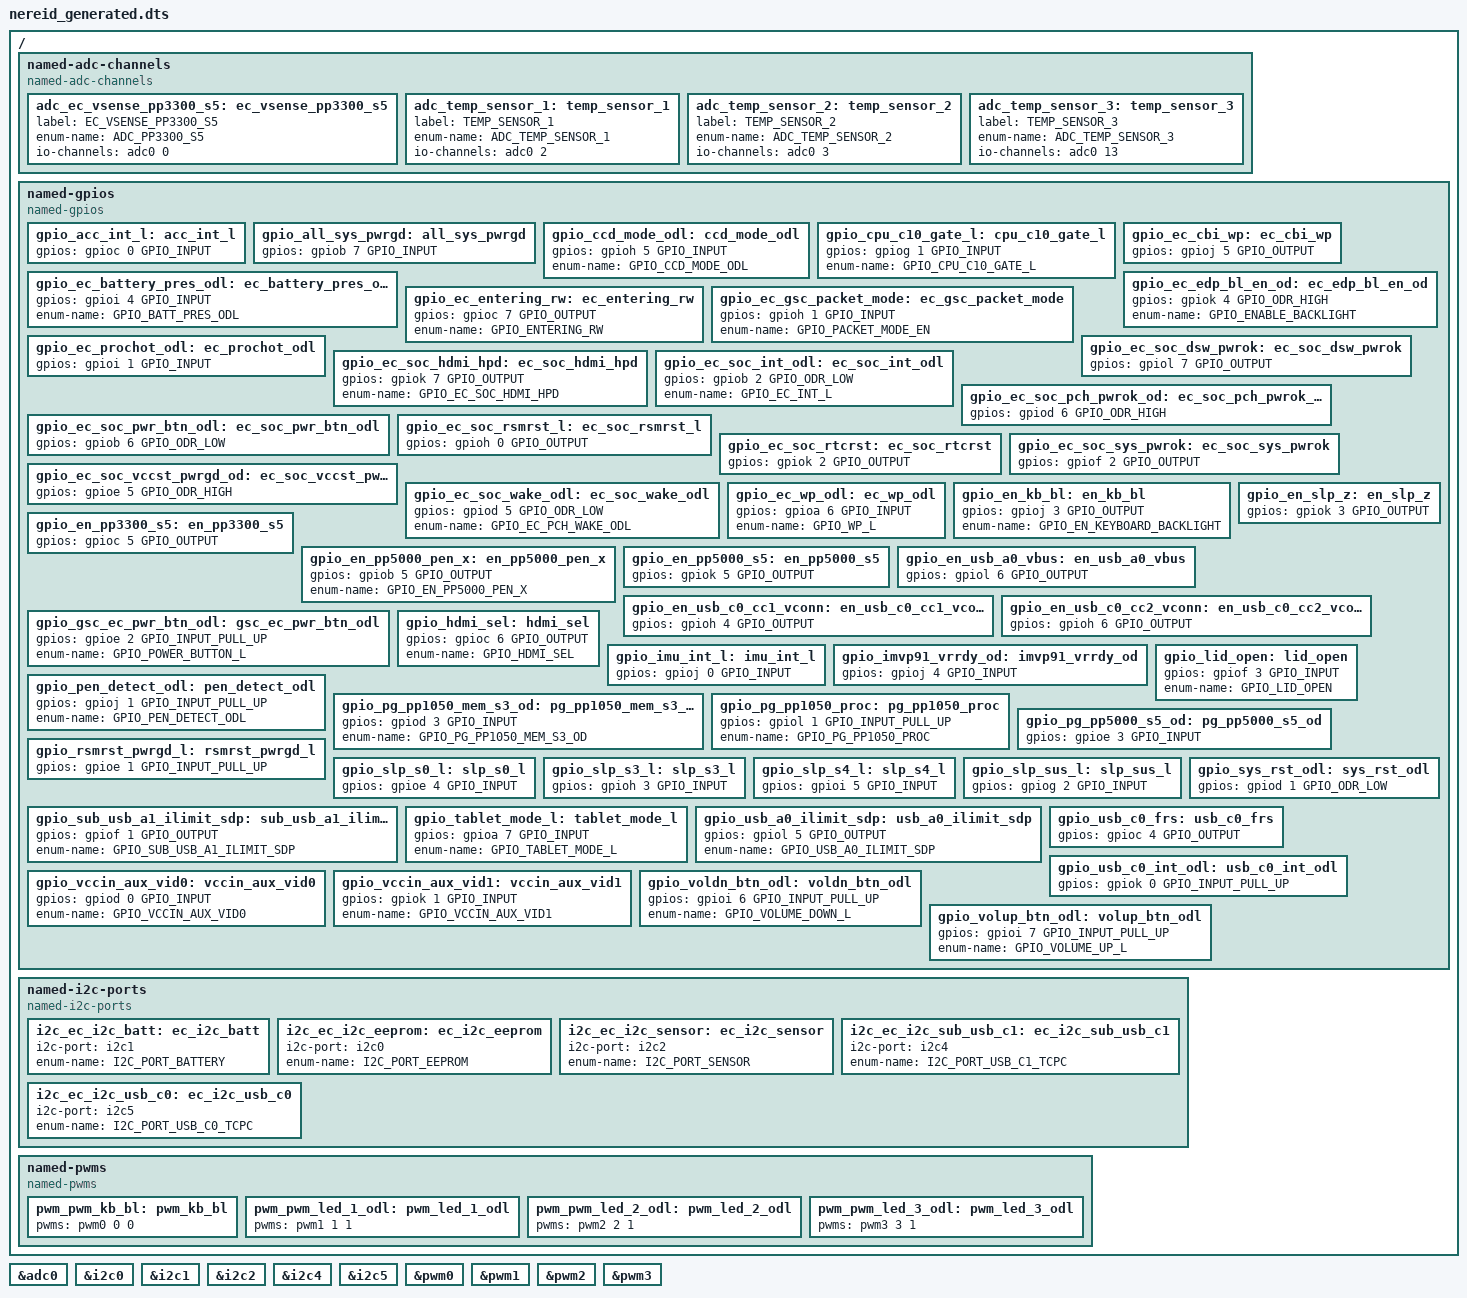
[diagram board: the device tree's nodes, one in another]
/* Copyright 2021 The Chromium OS Authors. All rights reserved.
 * Use of this source code is governed by a BSD-style license that can be
 * found in the LICENSE file.
 *
 * This file is auto-generated - do not edit!
 */

/ {

	named-adc-channels {
		compatible = "named-adc-channels";

		adc_ec_vsense_pp3300_s5: ec_vsense_pp3300_s5 {
			label = "EC_VSENSE_PP3300_S5";
			enum-name = "ADC_PP3300_S5";
			io-channels = <&adc0 0>;
		};
		adc_temp_sensor_1: temp_sensor_1 {
			label = "TEMP_SENSOR_1";
			enum-name = "ADC_TEMP_SENSOR_1";
			io-channels = <&adc0 2>;
		};
		adc_temp_sensor_2: temp_sensor_2 {
			label = "TEMP_SENSOR_2";
			enum-name = "ADC_TEMP_SENSOR_2";
			io-channels = <&adc0 3>;
		};
		adc_temp_sensor_3: temp_sensor_3 {
			label = "TEMP_SENSOR_3";
			enum-name = "ADC_TEMP_SENSOR_3";
			io-channels = <&adc0 13>;
		};
	};

	named-gpios {
		compatible = "named-gpios";

		gpio_acc_int_l: acc_int_l {
			#gpio-cells = <0>;
			gpios = <&gpioc 0 GPIO_INPUT>;
		};
		gpio_all_sys_pwrgd: all_sys_pwrgd {
			#gpio-cells = <0>;
			gpios = <&gpiob 7 GPIO_INPUT>;
		};
		gpio_ccd_mode_odl: ccd_mode_odl {
			#gpio-cells = <0>;
			gpios = <&gpioh 5 GPIO_INPUT>;
			enum-name = "GPIO_CCD_MODE_ODL";
		};
		gpio_cpu_c10_gate_l: cpu_c10_gate_l {
			#gpio-cells = <0>;
			gpios = <&gpiog 1 GPIO_INPUT>;
			enum-name = "GPIO_CPU_C10_GATE_L";
		};
		gpio_ec_battery_pres_odl: ec_battery_pres_odl {
			#gpio-cells = <0>;
			gpios = <&gpioi 4 GPIO_INPUT>;
			enum-name = "GPIO_BATT_PRES_ODL";
		};
		gpio_ec_cbi_wp: ec_cbi_wp {
			#gpio-cells = <0>;
			gpios = <&gpioj 5 GPIO_OUTPUT>;
		};
		gpio_ec_edp_bl_en_od: ec_edp_bl_en_od {
			#gpio-cells = <0>;
			gpios = <&gpiok 4 GPIO_ODR_HIGH>;
			enum-name = "GPIO_ENABLE_BACKLIGHT";
		};
		gpio_ec_entering_rw: ec_entering_rw {
			#gpio-cells = <0>;
			gpios = <&gpioc 7 GPIO_OUTPUT>;
			enum-name = "GPIO_ENTERING_RW";
		};
		gpio_ec_gsc_packet_mode: ec_gsc_packet_mode {
			#gpio-cells = <0>;
			gpios = <&gpioh 1 GPIO_INPUT>;
			enum-name = "GPIO_PACKET_MODE_EN";
		};
		gpio_ec_prochot_odl: ec_prochot_odl {
			#gpio-cells = <0>;
			gpios = <&gpioi 1 GPIO_INPUT>;
		};
		gpio_ec_soc_dsw_pwrok: ec_soc_dsw_pwrok {
			#gpio-cells = <0>;
			gpios = <&gpiol 7 GPIO_OUTPUT>;
		};
		gpio_ec_soc_hdmi_hpd: ec_soc_hdmi_hpd {
			#gpio-cells = <0>;
			gpios = <&gpiok 7 GPIO_OUTPUT>;
			enum-name = "GPIO_EC_SOC_HDMI_HPD";
		};
		gpio_ec_soc_int_odl: ec_soc_int_odl {
			#gpio-cells = <0>;
			gpios = <&gpiob 2 GPIO_ODR_LOW>;
			enum-name = "GPIO_EC_INT_L";
		};
		gpio_ec_soc_pch_pwrok_od: ec_soc_pch_pwrok_od {
			#gpio-cells = <0>;
			gpios = <&gpiod 6 GPIO_ODR_HIGH>;
		};
		gpio_ec_soc_pwr_btn_odl: ec_soc_pwr_btn_odl {
			#gpio-cells = <0>;
			gpios = <&gpiob 6 GPIO_ODR_LOW>;
		};
		gpio_ec_soc_rsmrst_l: ec_soc_rsmrst_l {
			#gpio-cells = <0>;
			gpios = <&gpioh 0 GPIO_OUTPUT>;
		};
		gpio_ec_soc_rtcrst: ec_soc_rtcrst {
			#gpio-cells = <0>;
			gpios = <&gpiok 2 GPIO_OUTPUT>;
		};
		gpio_ec_soc_sys_pwrok: ec_soc_sys_pwrok {
			#gpio-cells = <0>;
			gpios = <&gpiof 2 GPIO_OUTPUT>;
		};
		gpio_ec_soc_vccst_pwrgd_od: ec_soc_vccst_pwrgd_od {
			#gpio-cells = <0>;
			gpios = <&gpioe 5 GPIO_ODR_HIGH>;
		};
		gpio_ec_soc_wake_odl: ec_soc_wake_odl {
			#gpio-cells = <0>;
			gpios = <&gpiod 5 GPIO_ODR_LOW>;
			enum-name = "GPIO_EC_PCH_WAKE_ODL";
		};
		gpio_ec_wp_odl: ec_wp_odl {
			#gpio-cells = <0>;
			gpios = <&gpioa 6 GPIO_INPUT>;
			enum-name = "GPIO_WP_L";
		};
		gpio_en_kb_bl: en_kb_bl {
			#gpio-cells = <0>;
			gpios = <&gpioj 3 GPIO_OUTPUT>;
			enum-name = "GPIO_EN_KEYBOARD_BACKLIGHT";
		};
		gpio_en_pp3300_s5: en_pp3300_s5 {
			#gpio-cells = <0>;
			gpios = <&gpioc 5 GPIO_OUTPUT>;
		};
		gpio_en_pp5000_pen_x: en_pp5000_pen_x {
			#gpio-cells = <0>;
			gpios = <&gpiob 5 GPIO_OUTPUT>;
			enum-name = "GPIO_EN_PP5000_PEN_X";
		};
		gpio_en_pp5000_s5: en_pp5000_s5 {
			#gpio-cells = <0>;
			gpios = <&gpiok 5 GPIO_OUTPUT>;
		};
		gpio_en_slp_z: en_slp_z {
			#gpio-cells = <0>;
			gpios = <&gpiok 3 GPIO_OUTPUT>;
		};
		gpio_en_usb_a0_vbus: en_usb_a0_vbus {
			#gpio-cells = <0>;
			gpios = <&gpiol 6 GPIO_OUTPUT>;
		};
		gpio_en_usb_c0_cc1_vconn: en_usb_c0_cc1_vconn {
			#gpio-cells = <0>;
			gpios = <&gpioh 4 GPIO_OUTPUT>;
		};
		gpio_en_usb_c0_cc2_vconn: en_usb_c0_cc2_vconn {
			#gpio-cells = <0>;
			gpios = <&gpioh 6 GPIO_OUTPUT>;
		};
		gpio_gsc_ec_pwr_btn_odl: gsc_ec_pwr_btn_odl {
			#gpio-cells = <0>;
			gpios = <&gpioe 2 GPIO_INPUT_PULL_UP>;
			enum-name = "GPIO_POWER_BUTTON_L";
		};
		gpio_hdmi_sel: hdmi_sel {
			#gpio-cells = <0>;
			gpios = <&gpioc 6 GPIO_OUTPUT>;
			enum-name = "GPIO_HDMI_SEL";
		};
		gpio_imu_int_l: imu_int_l {
			#gpio-cells = <0>;
			gpios = <&gpioj 0 GPIO_INPUT>;
		};
		gpio_imvp91_vrrdy_od: imvp91_vrrdy_od {
			#gpio-cells = <0>;
			gpios = <&gpioj 4 GPIO_INPUT>;
		};
		gpio_lid_open: lid_open {
			#gpio-cells = <0>;
			gpios = <&gpiof 3 GPIO_INPUT>;
			enum-name = "GPIO_LID_OPEN";
		};
		gpio_pen_detect_odl: pen_detect_odl {
			#gpio-cells = <0>;
			gpios = <&gpioj 1 GPIO_INPUT_PULL_UP>;
			enum-name = "GPIO_PEN_DETECT_ODL";
		};
		gpio_pg_pp1050_mem_s3_od: pg_pp1050_mem_s3_od {
			#gpio-cells = <0>;
			gpios = <&gpiod 3 GPIO_INPUT>;
			enum-name = "GPIO_PG_PP1050_MEM_S3_OD";
		};
		gpio_pg_pp1050_proc: pg_pp1050_proc {
			#gpio-cells = <0>;
			gpios = <&gpiol 1 GPIO_INPUT_PULL_UP>;
			enum-name = "GPIO_PG_PP1050_PROC";
		};
		gpio_pg_pp5000_s5_od: pg_pp5000_s5_od {
			#gpio-cells = <0>;
			gpios = <&gpioe 3 GPIO_INPUT>;
		};
		gpio_rsmrst_pwrgd_l: rsmrst_pwrgd_l {
			#gpio-cells = <0>;
			gpios = <&gpioe 1 GPIO_INPUT_PULL_UP>;
		};
		gpio_slp_s0_l: slp_s0_l {
			#gpio-cells = <0>;
			gpios = <&gpioe 4 GPIO_INPUT>;
		};
		gpio_slp_s3_l: slp_s3_l {
			#gpio-cells = <0>;
			gpios = <&gpioh 3 GPIO_INPUT>;
		};
		gpio_slp_s4_l: slp_s4_l {
			#gpio-cells = <0>;
			gpios = <&gpioi 5 GPIO_INPUT>;
		};
		gpio_slp_sus_l: slp_sus_l {
			#gpio-cells = <0>;
			gpios = <&gpiog 2 GPIO_INPUT>;
		};
		gpio_sub_usb_a1_ilimit_sdp: sub_usb_a1_ilimit_sdp {
			#gpio-cells = <0>;
			gpios = <&gpiof 1 GPIO_OUTPUT>;
			enum-name = "GPIO_SUB_USB_A1_ILIMIT_SDP";
		};
		gpio_sys_rst_odl: sys_rst_odl {
			#gpio-cells = <0>;
			gpios = <&gpiod 1 GPIO_ODR_LOW>;
		};
		gpio_tablet_mode_l: tablet_mode_l {
			#gpio-cells = <0>;
			gpios = <&gpioa 7 GPIO_INPUT>;
			enum-name = "GPIO_TABLET_MODE_L";
		};
		gpio_usb_a0_ilimit_sdp: usb_a0_ilimit_sdp {
			#gpio-cells = <0>;
			gpios = <&gpiol 5 GPIO_OUTPUT>;
			enum-name = "GPIO_USB_A0_ILIMIT_SDP";
		};
		gpio_usb_c0_frs: usb_c0_frs {
			#gpio-cells = <0>;
			gpios = <&gpioc 4 GPIO_OUTPUT>;
		};
		gpio_usb_c0_int_odl: usb_c0_int_odl {
			#gpio-cells = <0>;
			gpios = <&gpiok 0 GPIO_INPUT_PULL_UP>;
		};
		gpio_vccin_aux_vid0: vccin_aux_vid0 {
			#gpio-cells = <0>;
			gpios = <&gpiod 0 GPIO_INPUT>;
			enum-name = "GPIO_VCCIN_AUX_VID0";
		};
		gpio_vccin_aux_vid1: vccin_aux_vid1 {
			#gpio-cells = <0>;
			gpios = <&gpiok 1 GPIO_INPUT>;
			enum-name = "GPIO_VCCIN_AUX_VID1";
		};
		gpio_voldn_btn_odl: voldn_btn_odl {
			#gpio-cells = <0>;
			gpios = <&gpioi 6 GPIO_INPUT_PULL_UP>;
			enum-name = "GPIO_VOLUME_DOWN_L";
		};
		gpio_volup_btn_odl: volup_btn_odl {
			#gpio-cells = <0>;
			gpios = <&gpioi 7 GPIO_INPUT_PULL_UP>;
			enum-name = "GPIO_VOLUME_UP_L";
		};
	};

	named-i2c-ports {
		compatible = "named-i2c-ports";

		i2c_ec_i2c_batt: ec_i2c_batt {
			i2c-port = <&i2c1>;
			enum-name = "I2C_PORT_BATTERY";
		};
		i2c_ec_i2c_eeprom: ec_i2c_eeprom {
			i2c-port = <&i2c0>;
			enum-name = "I2C_PORT_EEPROM";
		};
		i2c_ec_i2c_sensor: ec_i2c_sensor {
			i2c-port = <&i2c2>;
			enum-name = "I2C_PORT_SENSOR";
		};
		i2c_ec_i2c_sub_usb_c1: ec_i2c_sub_usb_c1 {
			i2c-port = <&i2c4>;
			enum-name = "I2C_PORT_USB_C1_TCPC";
		};
		i2c_ec_i2c_usb_c0: ec_i2c_usb_c0 {
			i2c-port = <&i2c5>;
			enum-name = "I2C_PORT_USB_C0_TCPC";
		};
	};

	named-pwms {
		compatible = "named-pwms";

		pwm_pwm_kb_bl: pwm_kb_bl {
			pwms = <&pwm0 0 0>;
		};
		pwm_pwm_led_1_odl: pwm_led_1_odl {
			pwms = <&pwm1 1 1>;
		};
		pwm_pwm_led_2_odl: pwm_led_2_odl {
			pwms = <&pwm2 2 1>;
		};
		pwm_pwm_led_3_odl: pwm_led_3_odl {
			pwms = <&pwm3 3 1>;
		};
	};
};

&adc0 {
	status = "okay";
};

&i2c0 {
	status = "okay";
};

&i2c1 {
	status = "okay";
};

&i2c2 {
	status = "okay";
};

&i2c4 {
	status = "okay";
};

&i2c5 {
	status = "okay";
};

&pwm0 {
	status = "okay";
};

&pwm1 {
	status = "okay";
};

&pwm2 {
	status = "okay";
};

&pwm3 {
	status = "okay";
};
